AUTOSAR XML (schema 4-0-3)
package /AUTOSAR_Dcm/SwComponentTypes
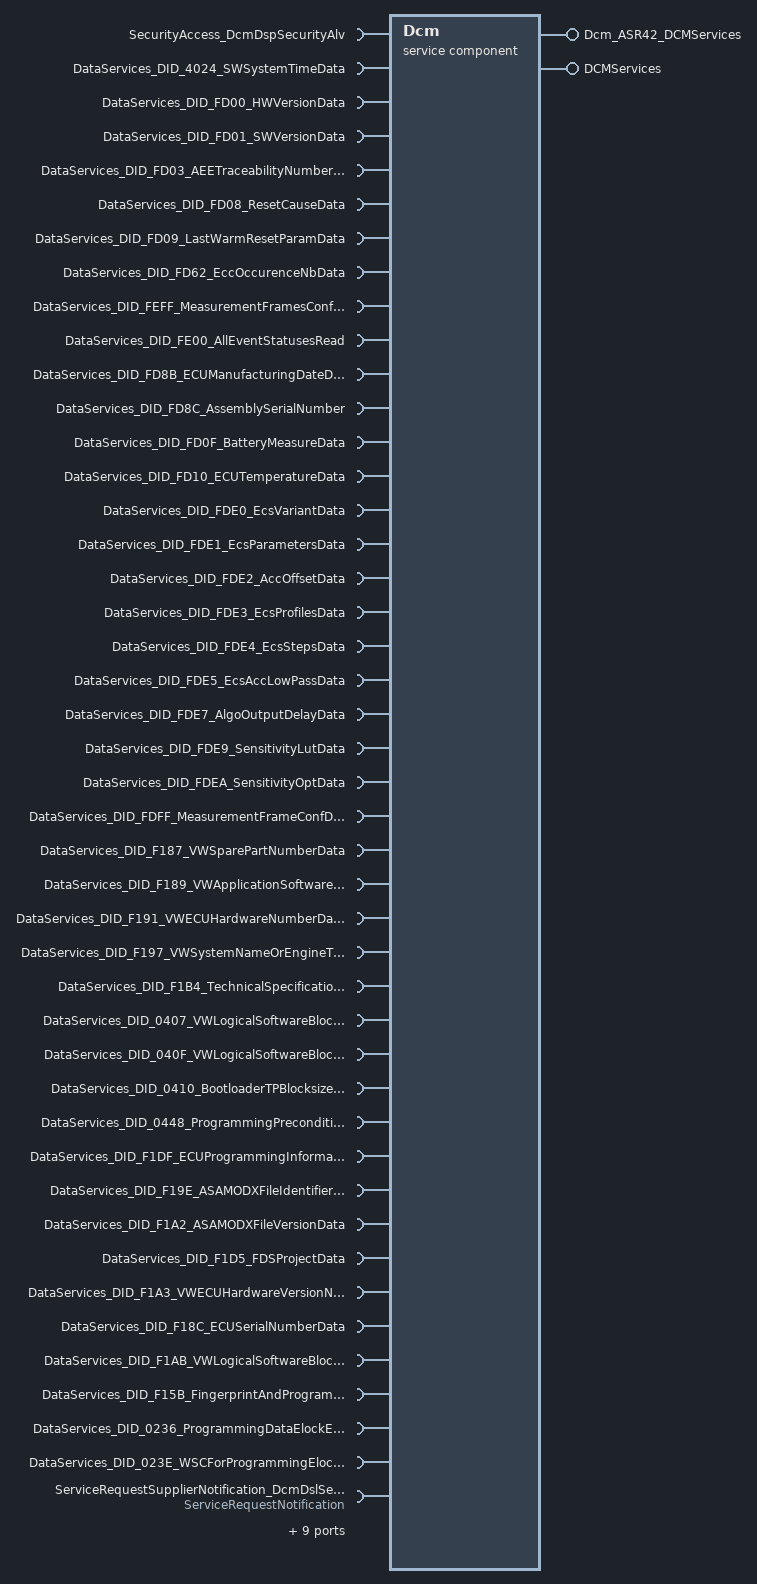
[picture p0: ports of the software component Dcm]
  service sw component type Dcm
    provide port Dcm_ASR42_DCMServices: provided-interface=Dcm_ASR42_DCMServices
      provided-com-specs:
        operation=GetSecurityLevel, queue-length=1
        operation=GetSesCtrlType, queue-length=1
        operation=GetActiveProtocol, queue-length=1
        operation=ResetToDefaultSession, queue-length=1
        operation=SetActiveDiagnostic, queue-length=1
    provide port DCMServices: provided-interface=DCMServices
      provided-com-specs:
        operation=GetSecurityLevel, queue-length=1
        operation=GetSesCtrlType, queue-length=1
        operation=GetActiveProtocol, queue-length=1
        operation=ResetToDefaultSession, queue-length=1
        operation=SetActiveDiagnostic, queue-length=1
    53 x require port:
      SecurityAccess_DcmDspSecurityAlv: required-interface=SecurityAccess_DcmDspSecurityAlv
      DataServices_DID_4024_SWSystemTimeData: required-interface=DataServices_DID_4024_SWSystemTimeData
      DataServices_DID_FD00_HWVersionData: required-interface=DataServices_DID_FD00_HWVersionData
      DataServices_DID_FD01_SWVersionData: required-interface=DataServices_DID_FD01_SWVersionData
      DataServices_DID_FD03_AEETraceabilityNumberData: required-interface=DataServices_DID_FD03_AEETraceabilityNumberData
      DataServices_DID_FD08_ResetCauseData: required-interface=DataServices_DID_FD08_ResetCauseData
      DataServices_DID_FD09_LastWarmResetParamData: required-interface=DataServices_DID_FD09_LastWarmResetParamData
      DataServices_DID_FD62_EccOccurenceNbData: required-interface=DataServices_DID_FD62_EccOccurenceNbData
      DataServices_DID_FEFF_MeasurementFramesConfData: required-interface=DataServices_DID_FEFF_MeasurementFramesConfData
      DataServices_DID_FE00_AllEventStatusesRead: required-interface=DataServices_DID_FE00_AllEventStatusesRead
      DataServices_DID_FD8B_ECUManufacturingDateData: required-interface=DataServices_DID_FD8B_ECUManufacturingDateData
      DataServices_DID_FD8C_AssemblySerialNumber: required-interface=DataServices_DID_FD8C_AssemblySerialNumber
      DataServices_DID_FD0F_BatteryMeasureData: required-interface=DataServices_DID_FD0F_BatteryMeasureData
      DataServices_DID_FD10_ECUTemperatureData: required-interface=DataServices_DID_FD10_ECUTemperatureData
      DataServices_DID_FDE0_EcsVariantData: required-interface=DataServices_DID_FDE0_EcsVariantData
      DataServices_DID_FDE1_EcsParametersData: required-interface=DataServices_DID_FDE1_EcsParametersData
      DataServices_DID_FDE2_AccOffsetData: required-interface=DataServices_DID_FDE2_AccOffsetData
      DataServices_DID_FDE3_EcsProfilesData: required-interface=DataServices_DID_FDE3_EcsProfilesData
      DataServices_DID_FDE4_EcsStepsData: required-interface=DataServices_DID_FDE4_EcsStepsData
      DataServices_DID_FDE5_EcsAccLowPassData: required-interface=DataServices_DID_FDE5_EcsAccLowPassData
      DataServices_DID_FDE7_AlgoOutputDelayData: required-interface=DataServices_DID_FDE7_AlgoOutputDelayData
      DataServices_DID_FDE9_SensitivityLutData: required-interface=DataServices_DID_FDE9_SensitivityLutData
      DataServices_DID_FDEA_SensitivityOptData: required-interface=DataServices_DID_FDEA_SensitivityOptData
      DataServices_DID_FDFF_MeasurementFrameConfDataRam: required-interface=DataServices_DID_FDFF_MeasurementFrameConfDataRam
      DataServices_DID_F187_VWSparePartNumberData: required-interface=DataServices_DID_F187_VWSparePartNumberData
      DataServices_DID_F189_VWApplicationSoftwareVersionNumberData: required-interface=DataServices_DID_F189_VWApplicationSoftwareVersionNumberData
      DataServices_DID_F191_VWECUHardwareNumberData: required-interface=DataServices_DID_F191_VWECUHardwareNumberData
      DataServices_DID_F197_VWSystemNameOrEngineTypeData: required-interface=DataServices_DID_F197_VWSystemNameOrEngineTypeData
      DataServices_DID_F1B4_TechnicalSpecificationsVersionData: required-interface=DataServices_DID_F1B4_TechnicalSpecificationsVersionData
      DataServices_DID_0407_VWLogicalSoftwareBlockCounterOfProgrammingAttemptsData: required-interface=DataServices_DID_0407_VWLogicalSoftwareBlockCounterOfProgrammingAttemptsData
      DataServices_DID_040F_VWLogicalSoftwareBlockLockValueData: required-interface=DataServices_DID_040F_VWLogicalSoftwareBlockLockValueData
      DataServices_DID_0410_BootloaderTPBlocksizeData: required-interface=DataServices_DID_0410_BootloaderTPBlocksizeData
      DataServices_DID_0448_ProgrammingPreconditionsData: required-interface=DataServices_DID_0448_ProgrammingPreconditionsData
      DataServices_DID_F1DF_ECUProgrammingInformationData: required-interface=DataServices_DID_F1DF_ECUProgrammingInformationData
      DataServices_DID_F19E_ASAMODXFileIdentifierData: required-interface=DataServices_DID_F19E_ASAMODXFileIdentifierData
      DataServices_DID_F1A2_ASAMODXFileVersionData: required-interface=DataServices_DID_F1A2_ASAMODXFileVersionData
      DataServices_DID_F1D5_FDSProjectData: required-interface=DataServices_DID_F1D5_FDSProjectData
      DataServices_DID_F1A3_VWECUHardwareVersionNumberData: required-interface=DataServices_DID_F1A3_VWECUHardwareVersionNumberData
      DataServices_DID_F18C_ECUSerialNumberData: required-interface=DataServices_DID_F18C_ECUSerialNumberData
      DataServices_DID_F1AB_VWLogicalSoftwareBlockVersionData: required-interface=DataServices_DID_F1AB_VWLogicalSoftwareBlockVersionData
      DataServices_DID_F15B_FingerprintAndProgrammingDateOfLogicalSoftwareBlocksData: required-interface=DataServices_DID_F15B_FingerprintAndProgrammingDateOfLogicalSoftwareBlocksData
      DataServices_DID_0236_ProgrammingDataElockEcuData: required-interface=DataServices_DID_0236_ProgrammingDataElockEcuData
      DataServices_DID_023E_WSCForProgrammingElockEcuData: required-interface=DataServices_DID_023E_WSCForProgrammingElockEcuData
      ServiceRequestSupplierNotification_DcmDslServiceRequestSupplierNotification: required-interface=ServiceRequestNotification
      RoutineServices_DcmDspRoutineCtrl_Lock_UnlockECU: required-interface=RoutineServices_DcmDspRoutineCtrl_Lock_UnlockECU
      RoutineServices_DcmDspRoutineProcessMode: required-interface=RoutineServices_DcmDspRoutineProcessMode
      RoutineServices_DcmDspRoutineAccCalib: required-interface=RoutineServices_DcmDspRoutineAccCalib
      RoutineServices_DcmDspRoutineLockSolenoid: required-interface=RoutineServices_DcmDspRoutineLockSolenoid
      RoutineServices_DcmDspRoutineEcuTempCalibration: required-interface=RoutineServices_DcmDspRoutineEcuTempCalibration
      RoutineServices_DcmDspRoutineAccAngleOffsetCalibration: required-interface=RoutineServices_DcmDspRoutineAccAngleOffsetCalibration
      RoutineServices_DcmDspRoutineRoutineCheckProgrammingPreconditions: required-interface=RoutineServices_DcmDspRoutineRoutineCheckProgrammingPreconditions
      CallBackDCMRequestServices_CBReqServInd_1: required-interface=CallbackDCMRequestServices
      DcmIf: required-interface=DcmIf
    behavior DcmIntBeh: handle-termination-and-restart=NO-SUPPORT, included-data-type-set=data-type=[Dcm_ASR42_DidSupportedType, Dcm_ASR42_ConfirmationStatusType, Dcm_ASR42_OpStatusType, Dcm_NegativeResponseCodeType, Dcm_DidSupportedType, Dcm_ConfirmationStatusType, Dcm_OpStatusType, Dcm_NegativeResponseCodeType]
      10 x operation invoked event:
        ASR42_EV_GetSecurityLevel: start-on-event=RE_GetSecurityLevel, operation=Dcm_ASR42_DCMServices.GetSecurityLevel
        ASR42_EV_GetSesCtrlType: start-on-event=RE_GetSesCtrlType, operation=Dcm_ASR42_DCMServices.GetSesCtrlType
        ASR42_EV_GetActiveProtocol: start-on-event=RE_GetActiveProtocol, operation=Dcm_ASR42_DCMServices.GetActiveProtocol
        ASR42_EV_ResetToDefaultSession: start-on-event=RE_ResetToDefaultSession, operation=Dcm_ASR42_DCMServices.ResetToDefaultSession
        ASR42_EV_SetActiveDiagnostic: start-on-event=RE_SetActiveDiagnostic, operation=Dcm_ASR42_DCMServices.SetActiveDiagnostic
        EV_GetSecurityLevel: start-on-event=RE_GetSecurityLevel, operation=DCMServices.GetSecurityLevel
        EV_GetSesCtrlType: start-on-event=RE_GetSesCtrlType, operation=DCMServices.GetSesCtrlType
        EV_GetActiveProtocol: start-on-event=RE_GetActiveProtocol, operation=DCMServices.GetActiveProtocol
        EV_ResetToDefaultSession: start-on-event=RE_ResetToDefaultSession, operation=DCMServices.ResetToDefaultSession
        EV_SetActiveDiagnostic: start-on-event=RE_SetActiveDiagnostic, operation=DCMServices.SetActiveDiagnostic
      port-api-options:
        enable-take-address=true, indirect-api=false, port=SecurityAccess_DcmDspSecurityAlv
        enable-take-address=true, indirect-api=false, port=DataServices_DID_4024_SWSystemTimeData
        enable-take-address=true, indirect-api=false, port=DataServices_DID_FD00_HWVersionData
        enable-take-address=true, indirect-api=false, port=DataServices_DID_FD01_SWVersionData
        enable-take-address=true, indirect-api=false, port=DataServices_DID_FD03_AEETraceabilityNumberData
        enable-take-address=true, indirect-api=false, port=DataServices_DID_FD08_ResetCauseData
        enable-take-address=true, indirect-api=false, port=DataServices_DID_FD09_LastWarmResetParamData
        enable-take-address=true, indirect-api=false, port=DataServices_DID_FD62_EccOccurenceNbData
        enable-take-address=true, indirect-api=false, port=DataServices_DID_FEFF_MeasurementFramesConfData
        enable-take-address=true, indirect-api=false, port=DataServices_DID_FE00_AllEventStatusesRead
        enable-take-address=true, indirect-api=false, port=DataServices_DID_FD8B_ECUManufacturingDateData
        enable-take-address=true, indirect-api=false, port=DataServices_DID_FD8C_AssemblySerialNumber
        enable-take-address=true, indirect-api=false, port=DataServices_DID_FD0F_BatteryMeasureData
        enable-take-address=true, indirect-api=false, port=DataServices_DID_FD10_ECUTemperatureData
        enable-take-address=true, indirect-api=false, port=DataServices_DID_FDE0_EcsVariantData
        enable-take-address=true, indirect-api=false, port=DataServices_DID_FDE1_EcsParametersData
        enable-take-address=true, indirect-api=false, port=DataServices_DID_FDE2_AccOffsetData
        enable-take-address=true, indirect-api=false, port=DataServices_DID_FDE3_EcsProfilesData
        enable-take-address=true, indirect-api=false, port=DataServices_DID_FDE4_EcsStepsData
        enable-take-address=true, indirect-api=false, port=DataServices_DID_FDE5_EcsAccLowPassData
        enable-take-address=true, indirect-api=false, port=DataServices_DID_FDE7_AlgoOutputDelayData
        enable-take-address=true, indirect-api=false, port=DataServices_DID_FDE9_SensitivityLutData
        enable-take-address=true, indirect-api=false, port=DataServices_DID_FDEA_SensitivityOptData
        enable-take-address=true, indirect-api=false, port=DataServices_DID_FDFF_MeasurementFrameConfDataRam
        enable-take-address=true, indirect-api=false, port=DataServices_DID_F187_VWSparePartNumberData
        enable-take-address=true, indirect-api=false, port=DataServices_DID_F189_VWApplicationSoftwareVersionNumberData
        enable-take-address=true, indirect-api=false, port=DataServices_DID_F191_VWECUHardwareNumberData
        enable-take-address=true, indirect-api=false, port=DataServices_DID_F197_VWSystemNameOrEngineTypeData
        enable-take-address=true, indirect-api=false, port=DataServices_DID_F1B4_TechnicalSpecificationsVersionData
        enable-take-address=true, indirect-api=false, port=DataServices_DID_0407_VWLogicalSoftwareBlockCounterOfProgrammingAttemptsData
        enable-take-address=true, indirect-api=false, port=DataServices_DID_040F_VWLogicalSoftwareBlockLockValueData
        enable-take-address=true, indirect-api=false, port=DataServices_DID_0410_BootloaderTPBlocksizeData
        enable-take-address=true, indirect-api=false, port=DataServices_DID_0448_ProgrammingPreconditionsData
        enable-take-address=true, indirect-api=false, port=DataServices_DID_F1DF_ECUProgrammingInformationData
        enable-take-address=true, indirect-api=false, port=DataServices_DID_F19E_ASAMODXFileIdentifierData
        enable-take-address=true, indirect-api=false, port=DataServices_DID_F1A2_ASAMODXFileVersionData
        enable-take-address=true, indirect-api=false, port=DataServices_DID_F1D5_FDSProjectData
        enable-take-address=true, indirect-api=false, port=DataServices_DID_F1A3_VWECUHardwareVersionNumberData
        enable-take-address=true, indirect-api=false, port=DataServices_DID_F18C_ECUSerialNumberData
        enable-take-address=true, indirect-api=false, port=DataServices_DID_F1AB_VWLogicalSoftwareBlockVersionData
        enable-take-address=true, indirect-api=false, port=DataServices_DID_F15B_FingerprintAndProgrammingDateOfLogicalSoftwareBlocksData
        enable-take-address=true, indirect-api=false, port=DataServices_DID_0236_ProgrammingDataElockEcuData
        enable-take-address=true, indirect-api=false, port=DataServices_DID_023E_WSCForProgrammingElockEcuData
        enable-take-address=true, indirect-api=false, port=ServiceRequestSupplierNotification_DcmDslServiceRequestSupplierNotification
        enable-take-address=true, indirect-api=false, port=RoutineServices_DcmDspRoutineCtrl_Lock_UnlockECU
        enable-take-address=true, indirect-api=false, port=RoutineServices_DcmDspRoutineProcessMode
        enable-take-address=true, indirect-api=false, port=RoutineServices_DcmDspRoutineAccCalib
        enable-take-address=true, indirect-api=false, port=RoutineServices_DcmDspRoutineLockSolenoid
        enable-take-address=true, indirect-api=false, port=RoutineServices_DcmDspRoutineEcuTempCalibration
        enable-take-address=true, indirect-api=false, port=RoutineServices_DcmDspRoutineAccAngleOffsetCalibration
        enable-take-address=true, indirect-api=false, port=RoutineServices_DcmDspRoutineRoutineCheckProgrammingPreconditions
        enable-take-address=true, indirect-api=false, port=CallBackDCMRequestServices_CBReqServInd_1
        enable-take-address=true, indirect-api=false, port=DcmIf
      6 x runnable:
        RE_GetSecurityLevel: can-be-invoked-concurrently=true, symbol=Dcm_GetSecurityLevel
        RE_GetSesCtrlType: can-be-invoked-concurrently=true, symbol=Dcm_GetSesCtrlType
        RE_GetActiveProtocol: can-be-invoked-concurrently=true, symbol=Dcm_GetActiveProtocol
        RE_ResetToDefaultSession: can-be-invoked-concurrently=true, symbol=Dcm_ResetToDefaultSession
        RE_SetActiveDiagnostic: can-be-invoked-concurrently=true, symbol=Dcm_SetActiveDiagnostic
        RE_MainFunction: symbol=Dcm_MainFunction
          87 x sync call, all with timeout=0.0:
            sscp_SecurityAccessGetSeed_DcmDspSecurityAlv: operation=SecurityAccess_DcmDspSecurityAlv.GetSeed
            sscp_SecurityAccessCompareKey_DcmDspSecurityAlv: operation=SecurityAccess_DcmDspSecurityAlv.CompareKey
            sscp_DataServicesReadData_DID_4024_SWSystemTimeData: operation=DataServices_DID_4024_SWSystemTimeData.ReadData
            sscp_DataServicesWriteData_DID_FD00_HWVersionData: operation=DataServices_DID_FD00_HWVersionData.WriteData
            sscp_DataServicesReadData_DID_FD00_HWVersionData: operation=DataServices_DID_FD00_HWVersionData.ReadData
            sscp_DataServicesReadData_DID_FD01_SWVersionData: operation=DataServices_DID_FD01_SWVersionData.ReadData
            sscp_DataServicesWriteData_DID_FD03_AEETraceabilityNumberData: operation=DataServices_DID_FD03_AEETraceabilityNumberData.WriteData
            sscp_DataServicesReadData_DID_FD03_AEETraceabilityNumberData: operation=DataServices_DID_FD03_AEETraceabilityNumberData.ReadData
            sscp_DataServicesReadData_DID_FD08_ResetCauseData: operation=DataServices_DID_FD08_ResetCauseData.ReadData
            sscp_DataServicesReadData_DID_FD09_LastWarmResetParamData: operation=DataServices_DID_FD09_LastWarmResetParamData.ReadData
            sscp_DataServicesReadData_DID_FD62_EccOccurenceNbData: operation=DataServices_DID_FD62_EccOccurenceNbData.ReadData
            sscp_DataServicesWriteData_DID_FEFF_MeasurementFramesConfData: operation=DataServices_DID_FEFF_MeasurementFramesConfData.WriteData
            sscp_DataServicesReadData_DID_FEFF_MeasurementFramesConfData: operation=DataServices_DID_FEFF_MeasurementFramesConfData.ReadData
            sscp_DataServicesReadData_DID_FE00_AllEventStatusesRead: operation=DataServices_DID_FE00_AllEventStatusesRead.ReadData
            sscp_DataServicesWriteData_DID_FD8B_ECUManufacturingDateData: operation=DataServices_DID_FD8B_ECUManufacturingDateData.WriteData
            sscp_DataServicesReadData_DID_FD8B_ECUManufacturingDateData: operation=DataServices_DID_FD8B_ECUManufacturingDateData.ReadData
            sscp_DataServicesWriteData_DID_FD8C_AssemblySerialNumber: operation=DataServices_DID_FD8C_AssemblySerialNumber.WriteData
            sscp_DataServicesReadData_DID_FD8C_AssemblySerialNumber: operation=DataServices_DID_FD8C_AssemblySerialNumber.ReadData
            sscp_DataServicesReadData_DID_FD0F_BatteryMeasureData: operation=DataServices_DID_FD0F_BatteryMeasureData.ReadData
            sscp_DataServicesReadData_DID_FD10_ECUTemperatureData: operation=DataServices_DID_FD10_ECUTemperatureData.ReadData
            sscp_DataServicesWriteData_DID_FDE0_EcsVariantData: operation=DataServices_DID_FDE0_EcsVariantData.WriteData
            sscp_DataServicesReadData_DID_FDE0_EcsVariantData: operation=DataServices_DID_FDE0_EcsVariantData.ReadData
            sscp_DataServicesWriteData_DID_FDE1_EcsParametersData: operation=DataServices_DID_FDE1_EcsParametersData.WriteData
            sscp_DataServicesReadData_DID_FDE1_EcsParametersData: operation=DataServices_DID_FDE1_EcsParametersData.ReadData
            sscp_DataServicesWriteData_DID_FDE2_AccOffsetData: operation=DataServices_DID_FDE2_AccOffsetData.WriteData
            sscp_DataServicesReadData_DID_FDE2_AccOffsetData: operation=DataServices_DID_FDE2_AccOffsetData.ReadData
            sscp_DataServicesWriteData_DID_FDE3_EcsProfilesData: operation=DataServices_DID_FDE3_EcsProfilesData.WriteData
            sscp_DataServicesReadData_DID_FDE3_EcsProfilesData: operation=DataServices_DID_FDE3_EcsProfilesData.ReadData
            sscp_DataServicesWriteData_DID_FDE4_EcsStepsData: operation=DataServices_DID_FDE4_EcsStepsData.WriteData
            sscp_DataServicesReadData_DID_FDE4_EcsStepsData: operation=DataServices_DID_FDE4_EcsStepsData.ReadData
            sscp_DataServicesWriteData_DID_FDE5_EcsAccLowPassData: operation=DataServices_DID_FDE5_EcsAccLowPassData.WriteData
            sscp_DataServicesReadData_DID_FDE5_EcsAccLowPassData: operation=DataServices_DID_FDE5_EcsAccLowPassData.ReadData
            sscp_DataServicesWriteData_DID_FDE7_AlgoOutputDelayData: operation=DataServices_DID_FDE7_AlgoOutputDelayData.WriteData
            sscp_DataServicesReadData_DID_FDE7_AlgoOutputDelayData: operation=DataServices_DID_FDE7_AlgoOutputDelayData.ReadData
            sscp_DataServicesWriteData_DID_FDE9_SensitivityLutData: operation=DataServices_DID_FDE9_SensitivityLutData.WriteData
            sscp_DataServicesReadData_DID_FDE9_SensitivityLutData: operation=DataServices_DID_FDE9_SensitivityLutData.ReadData
            sscp_DataServicesWriteData_DID_FDEA_SensitivityOptData: operation=DataServices_DID_FDEA_SensitivityOptData.WriteData
            sscp_DataServicesReadData_DID_FDEA_SensitivityOptData: operation=DataServices_DID_FDEA_SensitivityOptData.ReadData
            sscp_DataServicesWriteData_DID_FDFF_MeasurementFrameConfDataRam: operation=DataServices_DID_FDFF_MeasurementFrameConfDataRam.WriteData
            sscp_DataServicesReadData_DID_FDFF_MeasurementFrameConfDataRam: operation=DataServices_DID_FDFF_MeasurementFrameConfDataRam.ReadData
            sscp_DataServicesWriteData_DID_F187_VWSparePartNumberData: operation=DataServices_DID_F187_VWSparePartNumberData.WriteData
            sscp_DataServicesReadData_DID_F187_VWSparePartNumberData: operation=DataServices_DID_F187_VWSparePartNumberData.ReadData
            sscp_DataServicesWriteData_DID_F189_VWApplicationSoftwareVersionNumberData: operation=DataServices_DID_F189_VWApplicationSoftwareVersionNumberData.WriteData
            sscp_DataServicesReadData_DID_F189_VWApplicationSoftwareVersionNumberData: operation=DataServices_DID_F189_VWApplicationSoftwareVersionNumberData.ReadData
            sscp_DataServicesWriteData_DID_F191_VWECUHardwareNumberData: operation=DataServices_DID_F191_VWECUHardwareNumberData.WriteData
            sscp_DataServicesReadData_DID_F191_VWECUHardwareNumberData: operation=DataServices_DID_F191_VWECUHardwareNumberData.ReadData
            sscp_DataServicesWriteData_DID_F197_VWSystemNameOrEngineTypeData: operation=DataServices_DID_F197_VWSystemNameOrEngineTypeData.WriteData
            sscp_DataServicesReadData_DID_F197_VWSystemNameOrEngineTypeData: operation=DataServices_DID_F197_VWSystemNameOrEngineTypeData.ReadData
            sscp_DataServicesReadData_DID_F1B4_TechnicalSpecificationsVersionData: operation=DataServices_DID_F1B4_TechnicalSpecificationsVersionData.ReadData
            sscp_DataServicesReadData_DID_0407_VWLogicalSoftwareBlockCounterOfProgrammingAttemptsData: operation=DataServices_DID_0407_VWLogicalSoftwareBlockCounterOfProgrammingAttemptsData.ReadData
            sscp_DataServicesReadData_DID_040F_VWLogicalSoftwareBlockLockValueData: operation=DataServices_DID_040F_VWLogicalSoftwareBlockLockValueData.ReadData
            sscp_DataServicesWriteData_DID_0410_BootloaderTPBlocksizeData: operation=DataServices_DID_0410_BootloaderTPBlocksizeData.WriteData
            sscp_DataServicesReadData_DID_0410_BootloaderTPBlocksizeData: operation=DataServices_DID_0410_BootloaderTPBlocksizeData.ReadData
            sscp_DataServicesReadData_DID_0448_ProgrammingPreconditionsData: operation=DataServices_DID_0448_ProgrammingPreconditionsData.ReadData
            sscp_DataServicesReadData_DID_F1DF_ECUProgrammingInformationData: operation=DataServices_DID_F1DF_ECUProgrammingInformationData.ReadData
            sscp_DataServicesWriteData_DID_F19E_ASAMODXFileIdentifierData: operation=DataServices_DID_F19E_ASAMODXFileIdentifierData.WriteData
            sscp_DataServicesReadData_DID_F19E_ASAMODXFileIdentifierData: operation=DataServices_DID_F19E_ASAMODXFileIdentifierData.ReadData
            sscp_DataServicesWriteData_DID_F1A2_ASAMODXFileVersionData: operation=DataServices_DID_F1A2_ASAMODXFileVersionData.WriteData
            sscp_DataServicesReadData_DID_F1A2_ASAMODXFileVersionData: operation=DataServices_DID_F1A2_ASAMODXFileVersionData.ReadData
            sscp_DataServicesReadData_DID_F1D5_FDSProjectData: operation=DataServices_DID_F1D5_FDSProjectData.ReadData
            sscp_DataServicesWriteData_DID_F1A3_VWECUHardwareVersionNumberData: operation=DataServices_DID_F1A3_VWECUHardwareVersionNumberData.WriteData
            sscp_DataServicesReadData_DID_F1A3_VWECUHardwareVersionNumberData: operation=DataServices_DID_F1A3_VWECUHardwareVersionNumberData.ReadData
            sscp_DataServicesWriteData_DID_F18C_ECUSerialNumberData: operation=DataServices_DID_F18C_ECUSerialNumberData.WriteData
            sscp_DataServicesReadData_DID_F18C_ECUSerialNumberData: operation=DataServices_DID_F18C_ECUSerialNumberData.ReadData
            sscp_DataServicesReadData_DID_F1AB_VWLogicalSoftwareBlockVersionData: operation=DataServices_DID_F1AB_VWLogicalSoftwareBlockVersionData.ReadData
            sscp_DataServicesReadData_DID_F15B_FingerprintAndProgrammingDateOfLogicalSoftwareBlocksData: operation=DataServices_DID_F15B_FingerprintAndProgrammingDateOfLogicalSoftwareBlocksData.ReadData
            sscp_DataServicesWriteData_DID_0236_ProgrammingDataElockEcuData: operation=DataServices_DID_0236_ProgrammingDataElockEcuData.WriteData
            sscp_DataServicesReadData_DID_0236_ProgrammingDataElockEcuData: operation=DataServices_DID_0236_ProgrammingDataElockEcuData.ReadData
            sscp_DataServicesWriteData_DID_023E_WSCForProgrammingElockEcuData: operation=DataServices_DID_023E_WSCForProgrammingElockEcuData.WriteData
            sscp_DataServicesReadData_DID_023E_WSCForProgrammingElockEcuData: operation=DataServices_DID_023E_WSCForProgrammingElockEcuData.ReadData
            sscp_ServiceRequestSupplierNotificationIndication_DcmDslServiceRequestSupplierNotification: operation=ServiceRequestSupplierNotification_DcmDslServiceRequestSupplierNotification.Indication
            sscp_ServiceRequestSupplierNotificationConfirmation_DcmDslServiceRequestSupplierNotification: operation=ServiceRequestSupplierNotification_DcmDslServiceRequestSupplierNotification.Confirmation
            sscp_RoutineServicesStart_DcmDspRoutineCtrl_Lock_UnlockECU: operation=RoutineServices_DcmDspRoutineCtrl_Lock_UnlockECU.Start
            sscp_RoutineServicesStop_DcmDspRoutineCtrl_Lock_UnlockECU: operation=RoutineServices_DcmDspRoutineCtrl_Lock_UnlockECU.Stop
            sscp_RoutineServicesRequestResults_DcmDspRoutineCtrl_Lock_UnlockECU: operation=RoutineServices_DcmDspRoutineCtrl_Lock_UnlockECU.RequestResults
            sscp_RoutineServicesStart_DcmDspRoutineProcessMode: operation=RoutineServices_DcmDspRoutineProcessMode.Start
            sscp_RoutineServicesStop_DcmDspRoutineProcessMode: operation=RoutineServices_DcmDspRoutineProcessMode.Stop
            sscp_RoutineServicesRequestResults_DcmDspRoutineProcessMode: operation=RoutineServices_DcmDspRoutineProcessMode.RequestResults
            sscp_RoutineServicesStart_DcmDspRoutineAccCalib: operation=RoutineServices_DcmDspRoutineAccCalib.Start
            sscp_RoutineServicesStart_DcmDspRoutineLockSolenoid: operation=RoutineServices_DcmDspRoutineLockSolenoid.Start
            sscp_RoutineServicesStop_DcmDspRoutineLockSolenoid: operation=RoutineServices_DcmDspRoutineLockSolenoid.Stop
            sscp_RoutineServicesStart_DcmDspRoutineEcuTempCalibration: operation=RoutineServices_DcmDspRoutineEcuTempCalibration.Start
            sscp_RoutineServicesStart_DcmDspRoutineAccAngleOffsetCalibration: operation=RoutineServices_DcmDspRoutineAccAngleOffsetCalibration.Start
            sscp_RoutineServicesStart_DcmDspRoutineRoutineCheckProgrammingPreconditions: operation=RoutineServices_DcmDspRoutineRoutineCheckProgrammingPreconditions.Start
            sscp_CallBackDCMRequestServicesStartProtocol_CBReqServInd_1: operation=CallBackDCMRequestServices_CBReqServInd_1.StartProtocol
            sscp_CallBackDCMRequestServicesStopProtocol_CBReqServInd_1: operation=CallBackDCMRequestServices_CBReqServInd_1.StopProtocol
            sscp_DcmIfDcmClearDTC: operation=DcmIf.DcmClearDTC
package /EB_Dcm/SwcImplementations
  swc implementation DcmImpl: programming-language=C, sw-version=4.14.7, vendor-id=1, behavior=DcmIntBeh
    code-descriptors:
      code Code: artifact-descriptors=autosar-engineering-object={short-label=EngObject, category=SWSRC}
    resource consumption Resources
      memory section CODE: sw-addrmethod=CODE
